# SIM3U164_B register map
File version: 1
CPU: 
Registers are 32-bit, read-write, reset 0x0 unless marked. A register's access mark holds for its fields unless they carry their own. Offsets are from the block's base; [hi:lo] are bit positions; <NAME> marks a mode.

## RSTSRC_0
Base 0x4002D060
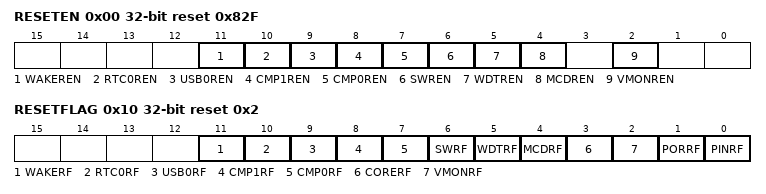
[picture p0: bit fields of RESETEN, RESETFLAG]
0x00 RESETEN reset 0x82F — System Reset Source Enable
  [11] WAKEREN — PMU Wakeup Reset Enable.
    1=ENABLED (Enable the PMU Wakeup event as a reset source.)
  [10] RTC0REN — RTC0 Reset Enable.
    0=DISABLED (Disable the RTC0 event as a reset source.); 1=ENABLED (Enable the RTC0 event as a reset source.)
  [9] USB0REN — USB0 Reset Enable.
    0=DISABLED (Disable the USB0 reset event as a reset source.); 1=ENABLED (Enable the USB0 reset event as a reset source.)
  [8] CMP1REN — Comparator 1 Reset Enable.
    0=DISABLED (Disable the Comparator 1 event as a reset source.); 1=ENABLED (Enable the Comparator 1 event as a reset source.)
  [7] CMP0REN — Comparator 0 Reset Enable.
    0=DISABLED (Disable the Comparator 0 event as a reset source.); 1=ENABLED (Enable the Comparator 0 event as a reset source.)
  [6] SWREN — Software Reset.
    0=DISABLED (Do not generate a Software Reset.); 1=ENABLED (Generate a Software Reset.)
  [5] WDTREN — Watchdog Timer Reset Enable.
    0=DISABLED (Disable the Watchdog Timer event as a reset source.); 1=ENABLED (Enable the Watchdog Timer event as a reset source.)
  [4] MCDREN — Missing Clock Detector Reset Enable.
    0=DISABLED (Disable the Missing Clock Detector event as a reset source.); 1=ENABLED (Enable the Missing Clock Detector event as a reset source.)
  [2] VMONREN — Voltage Supply Monitor VDD Reset Enable.
    0=DISABLED (Disable the Voltage Supply Monitor VDD event as a reset source.); 1=ENABLED (Enable the Voltage Supply Monitor VDD event as a reset source.)
0x10 RESETFLAG reset 0x2 — System Reset Flags
  [11] WAKERF ro — PMU Wakeup Reset Flag.
    0=NOT_SET (A PMU Wakeup event did not cause the last system reset.); 1=SET (A PMU Wakeup event caused the last system reset.)
  [10] RTC0RF ro — RTC0 Reset Flag.
    0=NOT_SET (An RTC0 event did not cause the last system reset.); 1=SET (An RTC0 event caused the last system reset.)
  [9] USB0RF ro — USB0 Reset Flag.
    0=NOT_SET (A USB0 Reset event did not cause the last system reset.); 1=SET (A USB0 Reset event caused the last system reset.)
  [8] CMP1RF ro — Comparator 1 Reset Flag.
    0=NOT_SET (A Comparator 1 event did not cause the last system reset.); 1=SET (A Comparator 1 event caused the last system reset.)
  [7] CMP0RF ro — Comparator 0 Reset Flag.
    0=NOT_SET (A Comparator 0 event did not cause the last system reset.); 1=SET (A Comparator 0 event caused the last system reset.)
  [6] SWRF ro — Software Reset Flag.
    0=NOT_SET (A Software Reset event did not cause the last system reset.); 1=SET (A Software Reset event caused the last system reset.)
  [5] WDTRF ro — Watchdog Timer Reset Flag.
    0=NOT_SET (A Watchdog Timer event did not cause the last system reset.); 1=SET (A Watchdog Timer event caused the last system reset.)
  [4] MCDRF ro — Missing Clock Detector Reset Flag.
    0=NOT_SET (A Missing Clock Detector event did not cause the last system reset.); 1=SET (A Missing Clock Detector event caused the last system reset.)
  [3] CORERF ro — Core Reset Flag.
    0=NOT_SET (A Core Reset event did not cause the last system reset.); 1=SET (A Core Reset event caused the last system reset.)
  [2] VMONRF ro — Voltage Supply Monitor VDD Reset Flag.
    0=NOT_SET (A Voltage Supply Monitor VDD Reset event did not cause the last system reset.); 1=SET (A Voltage Supply Monitor VDD Reset event caused the last system reset.)
  [1] PORRF ro — Power-On Reset Flag.
    0=NOT_SET (A Power-On Reset event did not cause the last system reset.); 1=SET (A Power-On Reset event caused the last system reset.)
  [0] PINRF ro — Pin Reset Flag.
    0=NOT_SET (A /RESET pin event did not cause the last system reset.); 1=SET (A /RESET pin event caused the last system reset.)
0x20 CONFIG — Configuration Options
  [0] PMSEL — Power Mode Select.
    0=PM9_DIS (Power Mode < PM9.); 1=PM9_EN (Power Mode = PM9.)
